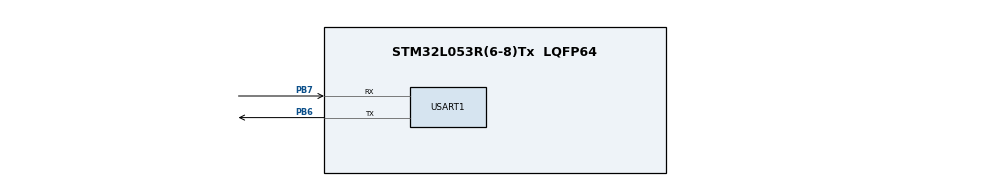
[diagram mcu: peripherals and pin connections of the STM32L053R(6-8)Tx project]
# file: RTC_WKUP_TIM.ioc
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Mcu.Family=STM32L0
Mcu.Name=STM32L053R(6-8)Tx
Mcu.Package=LQFP64
PB6.Mode=Asynchronous
PB6.Signal=USART1_TX
PB7.Mode=Asynchronous
PB7.Signal=USART1_RX
ProjectManager.HeapSize=0x200
ProjectManager.StackSize=0x400
ProjectManager.TargetToolchain=MDK-ARM V5
RCC.AHBFreq_Value=32000000
RCC.APB1Freq_Value=32000000
RCC.APB1TimFreq_Value=32000000
RCC.APB2Freq_Value=32000000
RCC.APB2TimFreq_Value=32000000
RCC.HCLKFreq_Value=32000000
RCC.HSE_VALUE=8000000
RCC.HSI16_VALUE=16000000
RCC.HSI48_VALUE=48000000
RCC.HSI_VALUE=16000000
RCC.LSE_VALUE=32768
RCC.MSI_VALUE=2097000
RCC.PLLMUL=RCC_PLLMUL_4
RCC.SYSCLKFreq_VALUE=32000000
RCC.SYSCLKSource=RCC_SYSCLKSOURCE_PLLCLK
RCC.VCOOutputFreq_Value=64000000
USART1.VirtualMode-Asynchronous=VM_ASYNC
VP_RTC_VS_RTC_Activate.Mode=RTC_Enabled
board=custom

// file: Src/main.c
/* USER CODE BEGIN Header */
/**
  ******************************************************************************
  * @file           : main.c
  * @brief          : Main program body
  ******************************************************************************
  * @attention
  *
  * <h2><center>&copy; Copyright (c) 2020 STMicroelectronics.
  * All rights reserved.</center></h2>
  *
  * This software component is licensed by ST under BSD 3-Clause license,
  * the "License"; You may not use this file except in compliance with the
  * License. You may obtain a copy of the License at:
  *                        opensource.org/licenses/BSD-3-Clause
  *
  ******************************************************************************
  */
/* USER CODE END Header */

#include "main.h"
#include "rtc.h"
#include "usart.h"
#include "gpio.h"

void SystemClock_Config(void);

/* USER CODE BEGIN 0 */
/**
  * @brief 进入睡眠
  * @retval
  */
void PWR_EnterDEEPSLEEPMode(void)
{
    __WFI();
}

/* USER CODE END 0 */

int main(void)
{

  /* MCU Configuration--------------------------------------------------------*/

  /* Reset of all peripherals, Initializes the Flash interface and the Systick. */

  LL_APB2_GRP1_EnableClock(LL_APB2_GRP1_PERIPH_SYSCFG);
  LL_APB1_GRP1_EnableClock(LL_APB1_GRP1_PERIPH_PWR);

  /* System interrupt init*/

  /* Configure the system clock */
  SystemClock_Config();

  /* Initialize all configured peripherals */
  MX_GPIO_Init();
  MX_RTC_Init();
  MX_USART1_UART_Init();
  /* USER CODE BEGIN 2 */
	rtc_INT_init(1000);					//1000ms唤醒一次
	printf("RTC 唤醒定时器周期唤醒低功耗模式 测试...\r\n");
  /* USER CODE END 2 */

  /* Infinite loop */
  while (1)
  {

    /* USER CODE BEGIN 3 */

		printf("Enter PWR_EnterDEEPSLEEPMode\r\n");
		PWR_EnterDEEPSLEEPMode();									//进去低功耗模式，再次阻塞程序运行，等待唤醒定时器唤醒

		printf("Quit  PWR_EnterWKUP!\r\n");				//此时已被唤醒

  }
  /* USER CODE END 3 */
}

void SystemClock_Config(void)
{
  LL_FLASH_SetLatency(LL_FLASH_LATENCY_1);

  if(LL_FLASH_GetLatency() != LL_FLASH_LATENCY_1)
  {
  Error_Handler();
  }
  LL_PWR_SetRegulVoltageScaling(LL_PWR_REGU_VOLTAGE_SCALE1);
  LL_RCC_HSI_Enable();

   /* Wait till HSI is ready */
  while(LL_RCC_HSI_IsReady() != 1)
  {

  }
  LL_RCC_HSI_SetCalibTrimming(16);
  LL_RCC_LSI_Enable();

   /* Wait till LSI is ready */
  while(LL_RCC_LSI_IsReady() != 1)
  {

  }
  LL_PWR_EnableBkUpAccess();
  LL_RCC_ForceBackupDomainReset();
  LL_RCC_ReleaseBackupDomainReset();
  LL_RCC_SetRTCClockSource(LL_RCC_RTC_CLKSOURCE_LSI);
  LL_RCC_EnableRTC();
  LL_RCC_PLL_ConfigDomain_SYS(LL_RCC_PLLSOURCE_HSI, LL_RCC_PLL_MUL_4, LL_RCC_PLL_DIV_2);
  LL_RCC_PLL_Enable();

   /* Wait till PLL is ready */
  while(LL_RCC_PLL_IsReady() != 1)
  {

  }
  LL_RCC_SetAHBPrescaler(LL_RCC_SYSCLK_DIV_1);
  LL_RCC_SetAPB1Prescaler(LL_RCC_APB1_DIV_1);
  LL_RCC_SetAPB2Prescaler(LL_RCC_APB2_DIV_1);
  LL_RCC_SetSysClkSource(LL_RCC_SYS_CLKSOURCE_PLL);

   /* Wait till System clock is ready */
  while(LL_RCC_GetSysClkSource() != LL_RCC_SYS_CLKSOURCE_STATUS_PLL)
  {

  }

  LL_Init1msTick(32000000);

  LL_SetSystemCoreClock(32000000);
  LL_RCC_SetUSARTClockSource(LL_RCC_USART1_CLKSOURCE_PCLK2);
}

void Error_Handler(void)
{
}

/************************ (C) COPYRIGHT STMicroelectronics *****END OF FILE****/
